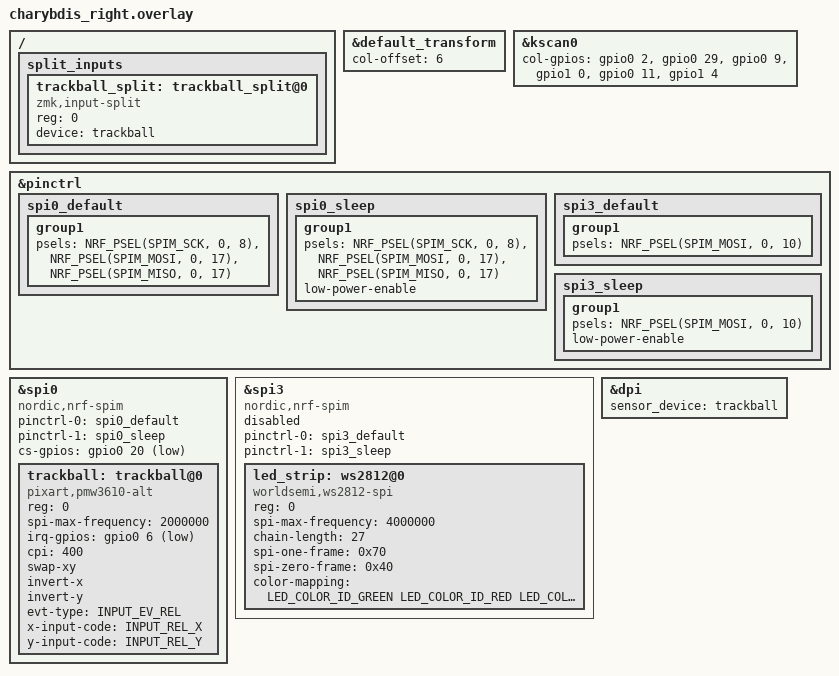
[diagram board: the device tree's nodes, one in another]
/*
 * Copyright (c) 2020 ZMK Contributors
 *
 * SPDX-License-Identifier: MIT
 */
 
#include "charybdis.dtsi"
#include <zephyr/dt-bindings/input/input-event-codes.h>

&default_transform {
    col-offset = <6>;
}; 

&kscan0 {
	col-gpios
		= <&gpio0 2 (GPIO_ACTIVE_HIGH | GPIO_PULL_DOWN)>
		, <&gpio0 29 (GPIO_ACTIVE_HIGH | GPIO_PULL_DOWN)>
		, <&gpio0 9 (GPIO_ACTIVE_HIGH | GPIO_PULL_DOWN)>
		, <&gpio1 0  (GPIO_ACTIVE_HIGH | GPIO_PULL_DOWN)>
		, <&gpio0 11 (GPIO_ACTIVE_HIGH | GPIO_PULL_DOWN)>
		, <&gpio1 4  (GPIO_ACTIVE_HIGH | GPIO_PULL_DOWN)>
		;
};

// trackball bus
&pinctrl {
    spi0_default: spi0_default {
        group1 {
            /* PMW3610 drives a single bidirectional SDIO line, so MOSI and
               MISO share P0.17. */
            psels = <NRF_PSEL(SPIM_SCK, 0, 8)>,
                <NRF_PSEL(SPIM_MOSI, 0, 17)>,
                <NRF_PSEL(SPIM_MISO, 0, 17)>;
        };
    };

    spi0_sleep: spi0_sleep {
        group1 {
            psels = <NRF_PSEL(SPIM_SCK, 0, 8)>,
                <NRF_PSEL(SPIM_MOSI, 0, 17)>,
                <NRF_PSEL(SPIM_MISO, 0, 17)>;
            low-power-enable;
        };
    };
};

&spi0 {
    status = "okay";
    compatible = "nordic,nrf-spim";
    pinctrl-0 = <&spi0_default>;
    pinctrl-1 = <&spi0_sleep>;
    pinctrl-names = "default", "sleep";
    cs-gpios = <&gpio0 20 GPIO_ACTIVE_LOW>;

    trackball: trackball@0 {
        status = "okay";
        compatible = "pixart,pmw3610-alt";
        reg = <0>;
        spi-max-frequency = <2000000>;
        irq-gpios = <&gpio0 6 (GPIO_ACTIVE_LOW | GPIO_PULL_UP)>;

        cpi = <400>;

        /* The sensor is mounted rotated. That fix-up now happens in the
           sensor's own orientation register instead of in driver code. The
           previous software mapping was (x, y) = (-raw_y, -raw_x), i.e. a
           swap plus both axes inverted. Both inversions are applied here, so
           this holds whether the chip inverts before or after the swap. */
        swap-xy;
        invert-x;
        invert-y;

        evt-type = <INPUT_EV_REL>;
        x-input-code = <INPUT_REL_X>;
        y-input-code = <INPUT_REL_Y>;
    };
};

/*
 * The right half is a peripheral now, so it only forwards raw motion. The
 * listener and the whole processor chain live on the dongle, which is where
 * layer state is. The reg address has to match the proxy node in
 * charybdis_dongle.overlay.
 */
/ {
    split_inputs {
        #address-cells = <1>;
        #size-cells = <0>;

        trackball_split: trackball_split@0 {
            compatible = "zmk,input-split";
            reg = <0>;
            device = <&trackball>;
        };
    };
};


//RGB bus
&pinctrl {
    spi3_default: spi3_default {
        group1 {
            psels = <NRF_PSEL(SPIM_MOSI, 0, 10)>;
        };
    };

    spi3_sleep: spi3_sleep {
        group1 {
            psels = <NRF_PSEL(SPIM_MOSI, 0, 10)>;
            low-power-enable;
        };
    };
};

&spi3 {
    compatible = "nordic,nrf-spim";
    /* Underglow is described but unused; the shared keymap used to turn this
       off, which the dongle cannot do since it has no spi3 LED strip. */
    status = "disabled";

    pinctrl-0 = <&spi3_default>;
    pinctrl-1 = <&spi3_sleep>;
    pinctrl-names = "default", "sleep";

    led_strip: ws2812@0 {
        compatible = "worldsemi,ws2812-spi";

        /* SPI */
        reg = <0>; /* ignored, but necessary for SPI bindings */
        spi-max-frequency = <4000000>;

        /* WS2812 */
        chain-length = <27>; /* number of LEDs */
        spi-one-frame = <0x70>;
        spi-zero-frame = <0x40>;
        color-mapping = <LED_COLOR_ID_GREEN
                         LED_COLOR_ID_RED
                         LED_COLOR_ID_BLUE>;
    };
};

/* The trackball lives here, so this is the only target that gives the CPI
   behavior a device to talk to. */
&dpi {
    sensor_device = <&trackball>;
};
